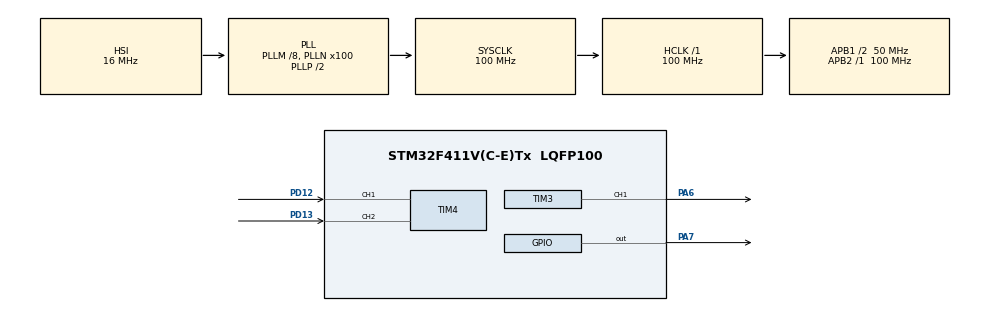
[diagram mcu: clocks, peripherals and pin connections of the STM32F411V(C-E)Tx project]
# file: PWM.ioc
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Mcu.Family=STM32F4
Mcu.Name=STM32F411V(C-E)Tx
Mcu.Package=LQFP100
NVIC.PriorityGroup=NVIC_PRIORITYGROUP_4
NVIC.TIM2_IRQn=true\:0\:0\:false\:false\:true\:true\:true\:true
PA6.Signal=S_TIM3_CH1
PA7.Signal=GPIO_Output
PD12.Signal=S_TIM4_CH1
PD13.Signal=S_TIM4_CH2
PH0\ -\ OSC_IN.Mode=HSE-External-Oscillator
PH0\ -\ OSC_IN.Signal=RCC_OSC_IN
PH1\ -\ OSC_OUT.Mode=HSE-External-Oscillator
PH1\ -\ OSC_OUT.Signal=RCC_OSC_OUT
ProjectManager.HeapSize=0x200
ProjectManager.StackSize=0x400
ProjectManager.TargetToolchain=STM32CubeIDE
RCC.48MHZClocksFreq_Value=50000000
RCC.AHBFreq_Value=100000000
RCC.APB1CLKDivider=RCC_HCLK_DIV2
RCC.APB1Freq_Value=50000000
RCC.APB1TimFreq_Value=100000000
RCC.APB2Freq_Value=100000000
RCC.APB2TimFreq_Value=100000000
RCC.CortexFreq_Value=100000000
RCC.HCLKFreq_Value=100000000
RCC.HSE_VALUE=25000000
RCC.HSI_VALUE=16000000
RCC.LSE_VALUE=32768
RCC.PLLM=8
RCC.PLLN=100
RCC.SYSCLKFreq_VALUE=100000000
RCC.SYSCLKSource=RCC_SYSCLKSOURCE_PLLCLK
RCC.VCOOutputFreq_Value=200000000
SH.S_TIM3_CH1.0=TIM3_CH1,PWM Generation1 CH1
SH.S_TIM4_CH1.0=TIM4_CH1,Encoder_Interface
SH.S_TIM4_CH2.0=TIM4_CH2,Encoder_Interface
TIM2.Period=9999
TIM2.Prescaler=9999
TIM3.Channel-PWM\ Generation1\ CH1=TIM_CHANNEL_1
TIM3.CounterMode=TIM_COUNTERMODE_UP
TIM4.EncoderMode=TIM_ENCODERMODE_TI12
VP_TIM2_VS_ClockSourceINT.Mode=Internal
VP_TIM3_VS_ClockSourceINT.Mode=Internal
board=custom

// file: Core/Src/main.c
#include "main.h"

/* USER CODE BEGIN PTD */
uint64_t envalue=0;
int i=0;
/* USER CODE END PTD */
int time=0;

TIM_HandleTypeDef htim2;
TIM_HandleTypeDef htim3;
TIM_HandleTypeDef htim4;

void SystemClock_Config(void);
static void MX_GPIO_Init(void);
static void MX_TIM3_Init(void);
static void MX_TIM4_Init(void);
static void MX_TIM2_Init(void);

int main(void)
{

  /* MCU Configuration--------------------------------------------------------*/

  /* Reset of all peripherals, Initializes the Flash interface and the Systick. */
  HAL_Init();

  /* Configure the system clock */
  SystemClock_Config();

  /* Initialize all configured peripherals */
  MX_GPIO_Init();
  MX_TIM3_Init();
  MX_TIM4_Init();
  MX_TIM2_Init();

  /* Infinite loop */
  /* USER CODE BEGIN WHILE */
  HAL_GPIO_WritePin(GPIOA, GPIO_PIN_7,1);
 // __HAL_TIM_SET_COMPARE(&htim3,TIM_CHANNEL_1,-99);
  __HAL_TIM_SET_COMPARE(&htim3,TIM_CHANNEL_1,0);
  HAL_TIM_PWM_Start(&htim3,TIM_CHANNEL_1);
  HAL_TIM_Encoder_Start(&htim4, TIM_CHANNEL_1);
  HAL_TIM_Encoder_Start(&htim4, TIM_CHANNEL_2);

  HAL_TIM_Base_Start_IT(&htim2);
  while (1)
  {
    /* USER CODE END WHILE */
	  envalue=__HAL_TIM_GET_COUNTER(&htim4);
	  if(envalue>=7392)
	  {
		  int a=envalue-7392;
		  i=i+1;
		  __HAL_TIM_SET_COUNTER(&htim4,a);
	  }
//	  i++;
//	  __HAL_TIM_SET_COMPARE(&htim3,TIM_CHANNEL_1,10*i);
//	  HAL_Delay(1000);
  }
}

void HAL_TIM_PeriodElapsedCallback(TIM_HandleTypeDef *htim)
{
  if (htim->Instance == htim2.Instance)
  {
	  time+=1;
	  if(time==5)
		  __HAL_TIM_SET_COMPARE(&htim3,TIM_CHANNEL_1,0);
  }
}
void SystemClock_Config(void)
{
  RCC_OscInitTypeDef RCC_OscInitStruct = {0};
  RCC_ClkInitTypeDef RCC_ClkInitStruct = {0};

  /** Configure the main internal regulator output voltage
  */
  __HAL_RCC_PWR_CLK_ENABLE();
  __HAL_PWR_VOLTAGESCALING_CONFIG(PWR_REGULATOR_VOLTAGE_SCALE1);

  /** Initializes the RCC Oscillators according to the specified parameters
  * in the RCC_OscInitTypeDef structure.
  */
  RCC_OscInitStruct.OscillatorType = RCC_OSCILLATORTYPE_HSI;
  RCC_OscInitStruct.HSIState = RCC_HSI_ON;
  RCC_OscInitStruct.HSICalibrationValue = RCC_HSICALIBRATION_DEFAULT;
  RCC_OscInitStruct.PLL.PLLState = RCC_PLL_ON;
  RCC_OscInitStruct.PLL.PLLSource = RCC_PLLSOURCE_HSI;
  RCC_OscInitStruct.PLL.PLLM = 8;
  RCC_OscInitStruct.PLL.PLLN = 100;
  RCC_OscInitStruct.PLL.PLLP = RCC_PLLP_DIV2;
  RCC_OscInitStruct.PLL.PLLQ = 4;
  if (HAL_RCC_OscConfig(&RCC_OscInitStruct) != HAL_OK)
  {
    Error_Handler();
  }

  /** Initializes the CPU, AHB and APB buses clocks
  */
  RCC_ClkInitStruct.ClockType = RCC_CLOCKTYPE_HCLK|RCC_CLOCKTYPE_SYSCLK
                              |RCC_CLOCKTYPE_PCLK1|RCC_CLOCKTYPE_PCLK2;
  RCC_ClkInitStruct.SYSCLKSource = RCC_SYSCLKSOURCE_PLLCLK;
  RCC_ClkInitStruct.AHBCLKDivider = RCC_SYSCLK_DIV1;
  RCC_ClkInitStruct.APB1CLKDivider = RCC_HCLK_DIV2;
  RCC_ClkInitStruct.APB2CLKDivider = RCC_HCLK_DIV1;

  if (HAL_RCC_ClockConfig(&RCC_ClkInitStruct, FLASH_LATENCY_3) != HAL_OK)
  {
    Error_Handler();
  }
}

static void MX_TIM2_Init(void)
{

  TIM_ClockConfigTypeDef sClockSourceConfig = {0};
  TIM_MasterConfigTypeDef sMasterConfig = {0};

  htim2.Instance = TIM2;
  htim2.Init.Prescaler = 9999;
  htim2.Init.CounterMode = TIM_COUNTERMODE_UP;
  htim2.Init.Period = 9999;
  htim2.Init.ClockDivision = TIM_CLOCKDIVISION_DIV1;
  htim2.Init.AutoReloadPreload = TIM_AUTORELOAD_PRELOAD_DISABLE;
  if (HAL_TIM_Base_Init(&htim2) != HAL_OK)
  {
    Error_Handler();
  }
  sClockSourceConfig.ClockSource = TIM_CLOCKSOURCE_INTERNAL;
  if (HAL_TIM_ConfigClockSource(&htim2, &sClockSourceConfig) != HAL_OK)
  {
    Error_Handler();
  }
  sMasterConfig.MasterOutputTrigger = TIM_TRGO_RESET;
  sMasterConfig.MasterSlaveMode = TIM_MASTERSLAVEMODE_DISABLE;
  if (HAL_TIMEx_MasterConfigSynchronization(&htim2, &sMasterConfig) != HAL_OK)
  {
    Error_Handler();
  }

}

static void MX_TIM3_Init(void)
{

  TIM_ClockConfigTypeDef sClockSourceConfig = {0};
  TIM_MasterConfigTypeDef sMasterConfig = {0};
  TIM_OC_InitTypeDef sConfigOC = {0};

  htim3.Instance = TIM3;
  htim3.Init.Prescaler = 499;
  htim3.Init.CounterMode = TIM_COUNTERMODE_UP;
  htim3.Init.Period = 99;
  htim3.Init.ClockDivision = TIM_CLOCKDIVISION_DIV1;
  htim3.Init.AutoReloadPreload = TIM_AUTORELOAD_PRELOAD_DISABLE;
  if (HAL_TIM_Base_Init(&htim3) != HAL_OK)
  {
    Error_Handler();
  }
  sClockSourceConfig.ClockSource = TIM_CLOCKSOURCE_INTERNAL;
  if (HAL_TIM_ConfigClockSource(&htim3, &sClockSourceConfig) != HAL_OK)
  {
    Error_Handler();
  }
  if (HAL_TIM_PWM_Init(&htim3) != HAL_OK)
  {
    Error_Handler();
  }
  sMasterConfig.MasterOutputTrigger = TIM_TRGO_RESET;
  sMasterConfig.MasterSlaveMode = TIM_MASTERSLAVEMODE_DISABLE;
  if (HAL_TIMEx_MasterConfigSynchronization(&htim3, &sMasterConfig) != HAL_OK)
  {
    Error_Handler();
  }
  sConfigOC.OCMode = TIM_OCMODE_PWM1;
  sConfigOC.Pulse = 0;
  sConfigOC.OCPolarity = TIM_OCPOLARITY_HIGH;
  sConfigOC.OCFastMode = TIM_OCFAST_DISABLE;
  if (HAL_TIM_PWM_ConfigChannel(&htim3, &sConfigOC, TIM_CHANNEL_1) != HAL_OK)
  {
    Error_Handler();
  }
  HAL_TIM_MspPostInit(&htim3);

}

static void MX_TIM4_Init(void)
{

  TIM_Encoder_InitTypeDef sConfig = {0};
  TIM_MasterConfigTypeDef sMasterConfig = {0};

  htim4.Instance = TIM4;
  htim4.Init.Prescaler = 0;
  htim4.Init.CounterMode = TIM_COUNTERMODE_UP;
  htim4.Init.Period = 65535;

  htim4.Init.ClockDivision = TIM_CLOCKDIVISION_DIV1;
  htim4.Init.AutoReloadPreload = TIM_AUTORELOAD_PRELOAD_DISABLE;
  sConfig.EncoderMode = TIM_ENCODERMODE_TI12;
  sConfig.IC1Polarity = TIM_ICPOLARITY_RISING;
  sConfig.IC1Selection = TIM_ICSELECTION_DIRECTTI;
  sConfig.IC1Prescaler = TIM_ICPSC_DIV1;
  sConfig.IC1Filter = 0;

  sConfig.IC2Polarity = TIM_ICPOLARITY_RISING;
  sConfig.IC2Selection = TIM_ICSELECTION_DIRECTTI;
  sConfig.IC2Prescaler = TIM_ICPSC_DIV1;
  sConfig.IC2Filter = 0;
  if (HAL_TIM_Encoder_Init(&htim4, &sConfig) != HAL_OK)
  {
    Error_Handler();
  }
  sMasterConfig.MasterOutputTrigger = TIM_TRGO_RESET;
  sMasterConfig.MasterSlaveMode = TIM_MASTERSLAVEMODE_DISABLE;
  if (HAL_TIMEx_MasterConfigSynchronization(&htim4, &sMasterConfig) != HAL_OK)
  {
    Error_Handler();
  }

}

static void MX_GPIO_Init(void)
{
  GPIO_InitTypeDef GPIO_InitStruct = {0};

  /* GPIO Ports Clock Enable */
  __HAL_RCC_GPIOH_CLK_ENABLE();
  __HAL_RCC_GPIOA_CLK_ENABLE();
  __HAL_RCC_GPIOD_CLK_ENABLE();

  /*Configure GPIO pin Output Level */
  HAL_GPIO_WritePin(GPIOA, GPIO_PIN_7, GPIO_PIN_RESET);

  /*Configure GPIO pin : PA7 */
  GPIO_InitStruct.Pin = GPIO_PIN_7;
  GPIO_InitStruct.Mode = GPIO_MODE_OUTPUT_PP;
  GPIO_InitStruct.Pull = GPIO_NOPULL;
  GPIO_InitStruct.Speed = GPIO_SPEED_FREQ_LOW;
  HAL_GPIO_Init(GPIOA, &GPIO_InitStruct);

}

void Error_Handler(void)
{
  __disable_irq();
  while (1)
  {
  }
}
